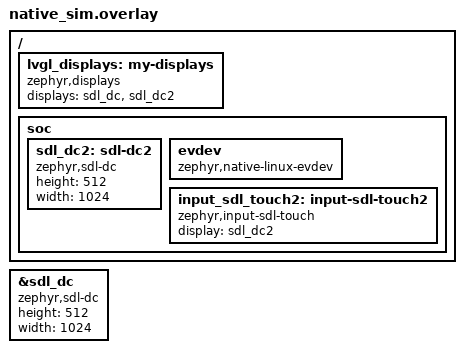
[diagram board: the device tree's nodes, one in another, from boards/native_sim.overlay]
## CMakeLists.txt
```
cmake_minimum_required(VERSION 3.20.0)

find_package(Zephyr REQUIRED HINTS $ENV{ZEPHYR_BASE})
project(3d_game_template_demo)

target_sources(app PRIVATE src/main.c src/editor_render.c src/editor_UI.c)

zephyr_include_directories(include)

set(TOOLS_FOLDER ${CMAKE_CURRENT_SOURCE_DIR}/../tools)

add_custom_command(
OUTPUT generated/generated_objects.h
COMMAND python3 ${CMAKE_CURRENT_SOURCE_DIR}/generate_objects.py ${TOOLS_FOLDER} ${CMAKE_CURRENT_SOURCE_DIR}/data generated
WORKING_DIRECTORY ${CMAKE_CURRENT_BINARY_DIR}
)

add_custom_target(generate_objects DEPENDS generated/generated_objects.h)

zephyr_include_directories(${CMAKE_CURRENT_BINARY_DIR}/generated)

add_dependencies(app generate_objects)
```

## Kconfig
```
menu "Zephyr"
source "Kconfig.zephyr"
endmenu

module = EDITOR
module-str = EDITOR
source "subsys/logging/Kconfig.template.log_config"
```

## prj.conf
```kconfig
CONFIG_DISPLAY=y
CONFIG_LOG=y
CONFIG_ENGINE=y
#CONFIG_LOG_DEFAULT_LEVEL=4
CONFIG_HEAP_MEM_POOL_SIZE=65536
CONFIG_INPUT=y
CONFIG_MAIN_STACK_SIZE=65536
CONFIG_TIMING_FUNCTIONS=y
CONFIG_SPEED_OPTIMIZATIONS=y
CONFIG_LOG_PERFORMANCE=n
CONFIG_TEST_RANDOM_GENERATOR=y
CONFIG_TIMER_RANDOM_GENERATOR=y
CONFIG_GPIO=y
CONFIG_MAX_OBJECTS=1048576
CONFIG_BLIT_THREAD=n

CONFIG_LVGL=y
CONFIG_LV_USE_LOG=y
CONFIG_LV_Z_MEM_POOL_SIZE=131072
CONFIG_SYS_HEAP_RUNTIME_STATS=y

CONFIG_LV_FONT_MONTSERRAT_12=y
CONFIG_LV_Z_FLUSH_THREAD=y
CONFIG_LV_FONT_UNSCII_8=y

CONFIG_JSON_LIBRARY=y
#CONFIG_FLASH=y
#CONFIG_FILE_SYSTEM=y
#CONFIG_FUSE_FS_ACCESS=y
#CONFIG_FLASH_SIMULATOR=y
```

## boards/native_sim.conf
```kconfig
CONFIG_SDL_DISPLAY_DEFAULT_PIXEL_FORMAT_L_8=y
CONFIG_SDL_DISPLAY_ZOOM_PCT=170
#CONFIG_SDL_DISPLAY_ZOOM_PCT=400
#CONFIG_SDL_DISPLAY_DEFAULT_PIXEL_FORMAT_RGB_565=y
CONFIG_RESOLUTION_X=1024
CONFIG_RESOLUTION_Y=512
CONFIG_TARGET_PROCESS_FPS=30
CONFIG_TARGET_RENDER_FPS=30
CONFIG_SYS_CLOCK_TICKS_PER_SEC=1000
```

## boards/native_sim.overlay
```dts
#include <zephyr/dt-bindings/input/input-event-codes.h>

&sdl_dc {
	compatible = "zephyr,sdl-dc";
	height = <512>;
	width = <1024>;
};

/ {
	/delete-property/ zephyr,display;

	lvgl_displays: my-displays {
		compatible = "zephyr,displays";
		displays = <&sdl_dc &sdl_dc2>;
		status = "okay";
	};

	soc {
		sdl_dc2: sdl-dc2 {
			compatible = "zephyr,sdl-dc";
			height = <512>;
			width = <1024>;
		};
		evdev: evdev {
			compatible = "zephyr,native-linux-evdev";
		};
		input_sdl_touch2: input-sdl-touch2 {
			compatible = "zephyr,input-sdl-touch";
			display = <&sdl_dc2>;
		};
	};
};
```

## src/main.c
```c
#include <zephyr/kernel.h>
#include <zephyr/device.h>
#include <zephyr/drivers/display.h>
#include <zephyr/input/input.h>
#include <zephyr/timing/timing.h>
#include <stdio.h>
#include <stdlib.h>
#include <zephyr/random/random.h>
#include <math.h>

#include <zephyr/logging/log.h>
LOG_MODULE_REGISTER(main);

#include "editor.h"

#include "engine.h"

L3_COLORTYPE blit_lvgl_buffer[L3_RESOLUTION_X * L3_RESOLUTION_Y];

int blit_display(L3_COLORTYPE *buffer, uint16_t x, uint16_t y, uint16_t size_x, uint16_t size_y)
{	/*struct display_buffer_descriptor buf_desc;
	buf_desc.buf_size = size_x * size_y;
		buf_desc.width = size_x;
	buf_desc.height = size_y;
	buf_desc.pitch = size_x;
		display_write(display_devices[0], 0, 0, &buf_desc, buffer);*/
	memcpy(blit_lvgl_buffer + x + y * L3_RESOLUTION_X, buffer, size_x*size_y);
	return 0;
}

typedef struct {
	L3_Unit vx;
	L3_Unit vy;
	L3_Unit z;
	L3_Unit x;
	L3_Unit speedmul;
	L3_Unit jump;
	L3_Unit xrot;
} Controls;

static Engine_Object* player = 0;
static Controls controls = {0};

static void process() {
	if (player != 0) {
		player->visual.transform.rotation.y += controls.vy;
		player->visual.transform.rotation.x += controls.vx;
		if (player->visual.transform.rotation.y > L3_F/2) player->visual.transform.rotation.y = -L3_F/2;
		if (player->visual.transform.rotation.y < -L3_F/2) player->visual.transform.rotation.y = L3_F/2;
		if (player->visual.transform.rotation.x > L3_F/2) player->visual.transform.rotation.x = -L3_F/2;
		if (player->visual.transform.rotation.x < -L3_F/2) player->visual.transform.rotation.x = L3_F/2;

		L3_Vec4 forward = {0, 0, L3_F, L3_F};
		L3_Vec4 left = {-L3_F, 0, 0, L3_F};
		L3_Mat4 transMat;

		L3_makeRotationMatrixZXY(player->visual.transform.rotation.x,
							player->visual.transform.rotation.y,
							0,
							transMat);

		L3_vec3Xmat4(&forward, transMat);
		L3_vec3Xmat4(&left, transMat);

		player->visual.transform.translation.x += controls.z * forward.x / L3_F;
		player->visual.transform.translation.y += controls.z * forward.y / L3_F;
		player->visual.transform.translation.z += controls.z * forward.z / L3_F;
		player->visual.transform.translation.x += controls.x * left.x / L3_F;
		player->visual.transform.translation.y += controls.x * left.y / L3_F;
		player->visual.transform.translation.z += controls.x * left.z / L3_F;

		L3_Camera *camera = engine_getcamera();
		camera->transform = player->visual.transform;
	}

	do_editor_UI();
}

static void update_controls(struct input_event *evt, void *user_data)
{
	Controls *cont = user_data;

	if (evt->code == INPUT_KEY_UP) {
		if (evt->value)
			cont->vx = 5;
		else
			cont->vx = 0;
	} else if (evt->code == INPUT_KEY_DOWN) {
		if (evt->value)
			cont->vx = -5;
		else
			cont->vx = 0;
	}
	if (evt->code == INPUT_KEY_LEFT) {
		if (evt->value)
			cont->vy = 15;
		else
			cont->vy = 0;
	} else if (evt->code == INPUT_KEY_RIGHT) {
		if (evt->value)
			cont->vy = -15;
		else
			cont->vy = 0;
	}
	if (evt->code == INPUT_KEY_W) {
		if (evt->value)
			cont->z = E_SPEED(5*L3_F*cont->speedmul);
		else
			cont->z = 0;
	} else if (evt->code == INPUT_KEY_S) {
		if (evt->value)
			cont->z = -E_SPEED(5*L3_F*cont->speedmul);
		else
			cont->z = 0;
	}

	if (evt->code == INPUT_KEY_A) {
		if (evt->value)
			cont->x = E_SPEED(5*L3_F*cont->speedmul);
		else
			cont->x = 0;
	} else if (evt->code == INPUT_KEY_D) {
		if (evt->value)
			cont->x = -E_SPEED(5*L3_F*cont->speedmul);
		else
			cont->x = 0;
	}

	if (evt->code == INPUT_KEY_LEFTSHIFT) {
		if (evt->value)
			cont->speedmul = 8;
		else
			cont->speedmul = 1;
	}
}

INPUT_CALLBACK_DEFINE(0, update_controls, &controls);

int main()
{
	if (!device_is_ready(display_devices[0])) {
		printf("Display device not ready");
		return 0;
	}

	timing_init();
	timing_start();

	k_msleep(100);
	display_blanking_on(display_devices[0]);
	display_blanking_on(display_devices[1]);
	//display_blanking_on(display_devices[2]);
	//display_set_pixel_format(display_device, PIXEL_FORMAT_L_8);
	display_blanking_off(display_devices[0]);
	display_blanking_off(display_devices[1]);
	//display_blanking_off(display_devices[2]);

	init_engine(&process);
	engine_UI_set_area(0, 0, L3_RESOLUTION_X, L3_RESOLUTION_Y);
	init_editor_UI();

	//engine_getcamera()->focalLength = 12;

	/* 'player' object */
	Engine_Object tmp = {0};
	L3_transform3DSet(0 * L3_F,0,-3*L3_F,0,0,0,L3_F,L3_F,L3_F,&(tmp.visual.transform));
	tmp.view_range = 16 * L3_F;
	tmp.visual_type = ENGINE_VISUAL_NOTHING;
	player = engine_add_object(tmp);

	//engine_set_statics(demo_scene, sizeof(demo_scene) / sizeof(*demo_scene));
	//engine_statics_enabled(true);

	controls.speedmul = 1;

	printf("obj cnt: %d\n", engine_object_getcnt() + engine_statics_getcnt());

	return 0;
}
```

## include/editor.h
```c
#pragma once

extern const struct device *display_devices[DT_ZEPHYR_DISPLAYS_COUNT];

int init_editor_render(void);
int init_editor_UI(void);
int do_editor_UI(void);
```

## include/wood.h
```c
#pragma once
static const L3_Unit wood_vertices[] = {
-65,18,980,
-64,-105,965,
-182,11,1024,
-180,-112,1010,
-678,192,-613,
-676,68,-627,
-795,185,-569,
-793,61,-583,
846,74,-74,
846,-74,-74,
846,74,74,
846,-74,74,
-846,74,-74,
-846,-74,-74,
-846,74,74,
-846,-74,74,
-429,350,556,
-438,231,582,
-560,343,479,
-569,224,505,
428,-32,-878,
419,-151,-851,
297,-39,-954,
288,-157,-928,
-43,-55,959,
-8,-169,922,
-163,-89,950,
-127,-203,913,
-66,467,-674,
-31,354,-711,
-186,433,-683,
-150,319,-720,
-538,328,-399,
-548,181,-427,
-426,339,-499,
-437,192,-527,
585,13,826,
574,-133,798,
696,23,726,
685,-122,699,
518,338,488,
532,217,496,
425,335,608,
439,215,617,
-823,110,-553,
-809,-10,-545,
-916,107,-433,
-902,-12,-425,
620,44,-821,
607,-79,-816,
715,38,-741,
702,-85,-735,
-471,218,490,
-484,94,496,
-376,212,570,
-389,88,576,
795,11,-551,
745,-102,-563,
845,-23,-442,
795,-136,-454,
-620,534,266,
-669,420,253,
-569,500,375,
-619,386,362,
};
static const L3_Index wood_indexes[] = {
4, 2, 0,
2, 7, 3,
6, 5, 7,
1, 7, 5,
1, 2, 3,
4, 1, 5,
12, 10, 8,
10, 15, 11,
14, 13, 15,
9, 15, 13,
8, 11, 9,
12, 9, 13,
20, 18, 16,
19, 22, 23,
23, 20, 21,
21, 19, 23,
16, 19, 17,
20, 17, 21,
28, 26, 24,
26, 31, 27,
30, 29, 31,
29, 27, 31,
25, 26, 27,
28, 25, 29,
36, 34, 32,
34, 39, 35,
39, 36, 37,
33, 39, 37,
33, 34, 35,
37, 32, 33,
44, 42, 40,
42, 47, 43,
46, 45, 47,
41, 47, 45,
40, 43, 41,
44, 41, 45,
48, 54, 50,
50, 55, 51,
54, 53, 55,
49, 55, 53,
48, 51, 49,
52, 49, 53,
56, 62, 58,
58, 63, 59,
62, 61, 63,
57, 63, 61,
57, 58, 59,
61, 56, 57,
4, 6, 2,
2, 6, 7,
6, 4, 5,
1, 3, 7,
1, 0, 2,
4, 0, 1,
12, 14, 10,
10, 14, 15,
14, 12, 13,
9, 11, 15,
8, 10, 11,
12, 8, 9,
20, 22, 18,
19, 18, 22,
23, 22, 20,
21, 17, 19,
16, 18, 19,
20, 16, 17,
28, 30, 26,
26, 30, 31,
30, 28, 29,
29, 25, 27,
25, 24, 26,
28, 24, 25,
36, 38, 34,
34, 38, 39,
39, 38, 36,
33, 35, 39,
33, 32, 34,
37, 36, 32,
44, 46, 42,
42, 46, 47,
46, 44, 45,
41, 43, 47,
40, 42, 43,
44, 40, 41,
48, 52, 54,
50, 54, 55,
54, 52, 53,
49, 51, 55,
48, 50, 51,
52, 48, 49,
56, 60, 62,
58, 62, 63,
62, 60, 61,
57, 59, 63,
57, 56, 58,
61, 60, 56,
};
static const L3_Model3D wood_model = {
.vertices = wood_vertices,
.triangleCount = 96,
.vertexCount = 64,
.triangles = wood_indexes,
};
static const L3_Object wood = {
.transform.scale.x = L3_F,
.transform.scale.y = L3_F,
.transform.scale.z = L3_F,
.transform.scale.w = 0,
.transform.translation.x = 0,
.transform.translation.y = 0,
.transform.translation.z = 0,
.transform.translation.w = L3_F,
.transform.rotation.x = 0,
.transform.rotation.y = 0,
.transform.rotation.z = 0,
.transform.rotation.w = L3_F,
.config.backfaceCulling = 2,
.config.visible = 2,
.model = &wood_model,
};
```

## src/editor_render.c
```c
#include <zephyr/kernel.h>
#include <zephyr/device.h>
#include <zephyr/drivers/display.h>
#include <zephyr/input/input.h>
#include <zephyr/timing/timing.h>
#include <stdio.h>
#include <stdlib.h>
#include <zephyr/random/random.h>
#include <math.h>

#include <zephyr/logging/log.h>
LOG_MODULE_REGISTER(editor_render);

#include "editor.h"

#include "engine.h"

#include "models/cube.h"

#include "models/plane.h"

#include "models/sphere.h"

#define ENUMERATE_DISPLAY_DEVS(node_id, prop, idx) DEVICE_DT_GET(DT_PROP_BY_IDX(node_id, prop, idx)),

const struct device *display_devices[DT_ZEPHYR_DISPLAYS_COUNT] = {
	DT_FOREACH_PROP_ELEM(DT_COMPAT_GET_ANY_STATUS_OKAY(zephyr_displays), displays, ENUMERATE_DISPLAY_DEVS)
};

L3_Object editor_colliders_objects_inst[L3_MAX_OBJECTS] = {0};

int blit_display2(L3_COLORTYPE *buffer, uint16_t size_x, uint16_t size_y)
{
	struct display_buffer_descriptor buf_desc;
	buf_desc.buf_size = size_x * size_y;
	buf_desc.width = size_x;
	buf_desc.height = size_y;
	buf_desc.pitch = size_x;

	display_write(display_devices[1], 0, 0, &buf_desc, buffer);
	return 0;
}

static L3_Object build_collider_representation(const Engine_Object *object, const E_Collider *collider)
{
	L3_Object out;

	out.transform = object->visual.transform;
	out.config.backfaceCulling = 0;
	out.config.visible = L3_VISIBLE_MODEL_WIREFRAME;
	switch (collider->type) {
		case ENGINE_COLLIDER_CUBE:
			out.model = &cube_model;
			out.transform.translation.x += collider->cube.offset.x;
			out.transform.translation.y += collider->cube.offset.y;
			out.transform.translation.z += collider->cube.offset.z;
			out.transform.scale.x = (out.transform.scale.x * collider->cube.size.x * 1) / L3_F;
			out.transform.scale.y = (out.transform.scale.y * collider->cube.size.y * 1) / L3_F;
			out.transform.scale.z = (out.transform.scale.z * collider->cube.size.z * 1) / L3_F;
			break;
		case ENGINE_COLLIDER_SPHERE:
			out.model = &sphere_model;
			out.transform.translation.x += collider->sphere.offset.x;
			out.transform.translation.y += collider->sphere.offset.y;
			out.transform.translation.z += collider->sphere.offset.z;
			out.transform.scale.x = (out.transform.scale.x * collider->sphere.size * 1) / L3_F;
			out.transform.scale.y = (out.transform.scale.x * collider->sphere.size * 1) / L3_F;
			out.transform.scale.z = (out.transform.scale.x * collider->sphere.size * 1) / L3_F;
			break;
		case ENGINE_COLLIDER_CAPSULE:
			out.model = &sphere_model;
			out.transform.translation.x += collider->capsule.offset.x;
			out.transform.translation.y += collider->capsule.offset.y;
			out.transform.translation.z += collider->capsule.offset.z;
			out.transform.scale.x = (out.transform.scale.x * collider->capsule.size.x * 1) / L3_F;
			out.transform.scale.y = (out.transform.scale.y * collider->capsule.size.y * 1) / L3_F;
			out.transform.scale.z = (out.transform.scale.z * collider->capsule.size.z * 1) / L3_F;
			break;
		case ENGINE_COLLIDER_APLANEX:
			out.model = &plane_model;
			out.transform.translation.x += collider->axisplane.offset.x;
			out.transform.translation.y += collider->axisplane.offset.y;
			out.transform.translation.z += collider->axisplane.offset.z;
			out.transform.rotation.z += 128;
			out.transform.scale.x = (out.transform.scale.x * collider->axisplane.size.y * 1) / L3_F;
			out.transform.scale.y = (out.transform.scale.y * collider->axisplane.size.x * 1) / L3_F;
			out.transform.scale.z = (out.transform.scale.z * collider->axisplane.size.z * 1) / L3_F;
			break;
		case ENGINE_COLLIDER_APLANEY:
			out.model = &plane_model;
			out.transform.translation.x += collider->axisplane.offset.x;
			out.transform.translation.y += collider->axisplane.offset.y;
			out.transform.translation.z += collider->axisplane.offset.z;
			out.transform.scale.x = (out.transform.scale.x * collider->axisplane.size.x * 1) / L3_F;
			out.transform.scale.y = (out.transform.scale.y * collider->axisplane.size.y * 1) / L3_F;
			out.transform.scale.z = (out.transform.scale.z * collider->axisplane.size.z * 1) / L3_F;
			break;
		case ENGINE_COLLIDER_APLANEZ:
			out.model = &plane_model;
			out.transform.translation.x += collider->axisplane.offset.x;
			out.transform.translation.y += collider->axisplane.offset.y;
			out.transform.translation.z += collider->axisplane.offset.z;
			out.transform.rotation.x += 128;
			out.transform.scale.x = (out.transform.scale.x * collider->axisplane.size.x * 1) / L3_F;
			out.transform.scale.y = (out.transform.scale.y * collider->axisplane.size.z * 1) / L3_F;
			out.transform.scale.z = (out.transform.scale.z * collider->axisplane.size.y * 1) / L3_F;
			break;
	}
	return out;
}

static void build_render_list_colliders(void)
{
	const L3_Object **render_o = engine_global_objects;
	int o_cnt = 0;
	L3_Vec4 forward = {0, 0, L3_F, L3_F};
	L3_Mat4 transMat;

	L3_makeRotationMatrixZXY(engine_camera.transform.rotation.x,
							engine_camera.transform.rotation.y,
							engine_camera.transform.rotation.z,
							transMat);

	L3_vec3Xmat4(&forward, transMat);

	for (int i = 0; i < engine_object_getcnt(); i++) {
		if (engine_getobjects()[i].visual_type > ENGINE_VISUAL_UNUSED) {
			if (o_cnt >= L3_MAX_OBJECTS) break;
			if (engine_getobjects()[i].view_range + 32000 <= L3_distanceManhattan(engine_getobjects()[i].visual.transform.translation, engine_camera.transform.translation)) continue;
			if (engine_getobjects()[i].collisions != 0) {
				for (int j = 0; j < engine_getobjects()[i].collisions->colliderCount; j++) {
					editor_colliders_objects_inst[o_cnt] = build_collider_representation(&(engine_getobjects()[i]), &(engine_getobjects()[i].collisions->colliders[j]));
					*render_o = &(editor_colliders_objects_inst[o_cnt]);
					render_o++;
					o_cnt++;
				}
			}
		}
	}
	engine_objectCount = o_cnt;
}

static void build_render_list(void)
{
	const L3_Object **render_o = engine_global_objects;
	size_t o_cnt = 0;
	L3_Vec4 forward = {0, 0, L3_F, L3_F};
	L3_Mat4 transMat;
	L3_Vec4 dir;
	L3_Unit dot;

	L3_makeRotationMatrixZXY(engine_camera.transform.rotation.x,
							engine_camera.transform.rotation.y,
							engine_camera.transform.rotation.z,
							transMat);

	L3_vec3Xmat4(&forward, transMat);

	for (int i = 0; i < engine_object_getcnt(); i++) {
		if (engine_getobjects()[i].visual_type >= ENGINE_VISUAL_MODEL) {
			if (o_cnt >= L3_MAX_OBJECTS) break;
			if (engine_getobjects()[i].view_range <= L3_distanceManhattan(engine_getobjects()[i].visual.transform.translation, engine_camera.transform.translation)) continue;
			dir.x = engine_getobjects()[i].visual.transform.translation.x - engine_camera.transform.translation.x;
			dir.y = engine_getobjects()[i].visual.transform.translation.y - engine_camera.transform.translation.y;
			dir.z = engine_getobjects()[i].visual.transform.translation.z - engine_camera.transform.translation.z;
			dot = L3_vec3Dot(forward, dir);
			if (dot < -ENGINE_REAR_OBJECT_CUTOFF) continue;
			*render_o = &(engine_getobjects()[i].visual);
			render_o++;
			o_cnt++;
		}
	}
	engine_objectCount = o_cnt;
}

int engine_render_hook_pre(void)
{
	/* clear process thread's list */
	build_render_list_colliders();

	L3_draw(engine_camera, engine_global_objects, engine_objectCount);
	blit_display2(L3_video_buffer, L3_RESOLUTION_X, L3_RESOLUTION_Y);

	/* clear viewport to black for actual frame */
	L3_newFrame();
	L3_clearScreen(0);
	/* regenerate process thread's list without statics*/
	build_render_list();

	return 0;
}
```

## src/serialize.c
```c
#include <zephyr/kernel.h>
#include <stdio.h>
#include <zephyr/data/json.h>
#include "engine.h"

typedef struct Engine_Object_Serialize_s {
	int			visual_type;
	int			view_range;
	int			backfaceCulling;
	int			visible;
	int 		solid_color;
	L3_Transform3D	transform;
	const char		*visual_i;
	const char		*collisions;
} Engine_Object_Serialize;


static const struct json_obj_descr L3_Vec4_descr[] = {
	JSON_OBJ_DESCR_PRIM(L3_Vec4, x, JSON_TOK_INT),
	JSON_OBJ_DESCR_PRIM(L3_Vec4, y, JSON_TOK_INT),
	JSON_OBJ_DESCR_PRIM(L3_Vec4, z, JSON_TOK_INT),
	JSON_OBJ_DESCR_PRIM(L3_Vec4, w, JSON_TOK_INT),
};

static const struct json_obj_descr L3_Transform3D_descr[] = {
	JSON_OBJ_DESCR_OBJECT(L3_Transform3D, translation, L3_Vec4_descr),
	JSON_OBJ_DESCR_OBJECT(L3_Transform3D, rotation, L3_Vec4_descr),
	JSON_OBJ_DESCR_OBJECT(L3_Transform3D, scale, L3_Vec4_descr),
};

static const struct json_obj_descr Engine_Object_Serialize_descr[] = {
	JSON_OBJ_DESCR_PRIM(Engine_Object_Serialize, visual_type, JSON_TOK_INT),
	JSON_OBJ_DESCR_PRIM(Engine_Object_Serialize, view_range, JSON_TOK_INT),
	JSON_OBJ_DESCR_PRIM(Engine_Object_Serialize, backfaceCulling, JSON_TOK_INT),
	JSON_OBJ_DESCR_PRIM(Engine_Object_Serialize, visible, JSON_TOK_INT),
	JSON_OBJ_DESCR_PRIM(Engine_Object_Serialize, solid_color, JSON_TOK_INT),
	JSON_OBJ_DESCR_OBJECT(Engine_Object_Serialize, transform, L3_Transform3D_descr),
	JSON_OBJ_DESCR_PRIM(Engine_Object_Serialize, visual_i, JSON_TOK_STRING),
	JSON_OBJ_DESCR_PRIM(Engine_Object_Serialize, collisions, JSON_TOK_STRING),
};

static Engine_Object_Serialize	engine_objects_serialize[CONFIG_MAX_OBJECTS] = {0};

static void objects_to_serialize()
{
	Engine_Object *objects = engine_getobjects();

	for (int i = 0; i < engine_object_getcnt(); i++) {
		engine_objects_serialize[i].visual_type = objects[i].visual_type;
		engine_objects_serialize[i].view_range = objects[i].view_range;
		engine_objects_serialize[i].backfaceCulling = objects[i].visual.config.backfaceCulling;
		engine_objects_serialize[i].visible = objects[i].visual.config.visible;
		engine_objects_serialize[i].transform = objects[i].visual.transform;
		engine_objects_serialize[i].solid_color = objects[i].visual.solid_color;
		int j = 0;
		bool found = false;
		for (; j < ARRAY_SIZE(generated_object_list); j++) {
			if (objects[i].visual.model == generated_object_list[j].visual.model ||
				objects[i].visual.billboard == generated_object_list[j].visual.billboard) {
				found = true;
				break;
			}
		}
		if (found) {
			engine_objects_serialize[i].visual_i = generated_object_visual_names[j];
			engine_objects_serialize[i].collisions = generated_object_collisions_names[j];
		} else {
			engine_objects_serialize[i].visual_i = 0;
			engine_objects_serialize[i].collisions = 0;
		}
	}
}

static void serialize_to_objects(int cnt)
{
	Engine_Object obj;
	obj.process = 0;
	obj.data = 0;

	for (int i = 0; i < cnt; i++) {
		obj.visual_type = engine_objects_serialize[i].visual_type;
		obj.view_range = engine_objects_serialize[i].view_range;
		obj.visual.config.backfaceCulling = engine_objects_serialize[i].backfaceCulling;
		obj.visual.config.visible = engine_objects_serialize[i].visible;
		obj.visual.transform = engine_objects_serialize[i].transform;
		obj.visual.solid_color = engine_objects_serialize[i].solid_color;
		int j = 0;
		bool found = false;
		for (; j < ARRAY_SIZE(generated_object_list); j++) {
			if (strcmp(generated_object_visual_names[j], engine_objects_serialize[i].visual_i) == 0) {
				found = true;
				break;
			}
		}
		if (obj.visual.config.visible & L3_VISIBLE_BILLBOARD) {
			obj.visual.billboard = generated_object_list[j].visual.billboard;
		} else {
			obj.visual.model = generated_object_list[j].visual.model;
		}
		obj.collisions = generated_object_list[j].collisions;
		engine_add_object(obj);
	}
}

int serialize_objects(char *buffer, size_t buflen)
{
	int ret = 0;
	size_t offset = 2;

	objects_to_serialize();
	buffer[0] = '[';
	buffer[1] = '\n';
	for (int i = 1; i < engine_object_getcnt(); i++) {
		ret = json_obj_encode_buf(Engine_Object_Serialize_descr, ARRAY_SIZE(Engine_Object_Serialize_descr), &(engine_objects_serialize[i]), buffer + offset, buflen - offset);
		offset += json_calc_encoded_len(Engine_Object_Serialize_descr, ARRAY_SIZE(Engine_Object_Serialize_descr), &(engine_objects_serialize[i])) + 2;
		if (i+1 < engine_object_getcnt()) {
			*(buffer + offset-2) = ',';
			*(buffer + offset-1) = '\n';
		} else {
			*(buffer + offset-2) = '\n';
			*(buffer + offset-1) = ']';
			*(buffer + offset) = 0;
		}
		if (ret < 0) return ret;
	}
	return ret;
}

int deserialize_objects(char *buffer, size_t buflen)
{
	int ret;
	struct json_obj json;
	size_t cnt = 0;

	ret = json_arr_separate_object_parse_init(&json, buffer, buflen);
	if (ret < 0) return ret;
	ret = json_arr_separate_parse_object(&json, Engine_Object_Serialize_descr, ARRAY_SIZE(Engine_Object_Serialize_descr), &(engine_objects_serialize[cnt]));
	while (ret > 0) {
		cnt++;
		ret = json_arr_separate_parse_object(&json, Engine_Object_Serialize_descr, ARRAY_SIZE(Engine_Object_Serialize_descr), &(engine_objects_serialize[cnt]));
	}

	serialize_to_objects(cnt);
	return ret;
}
```
